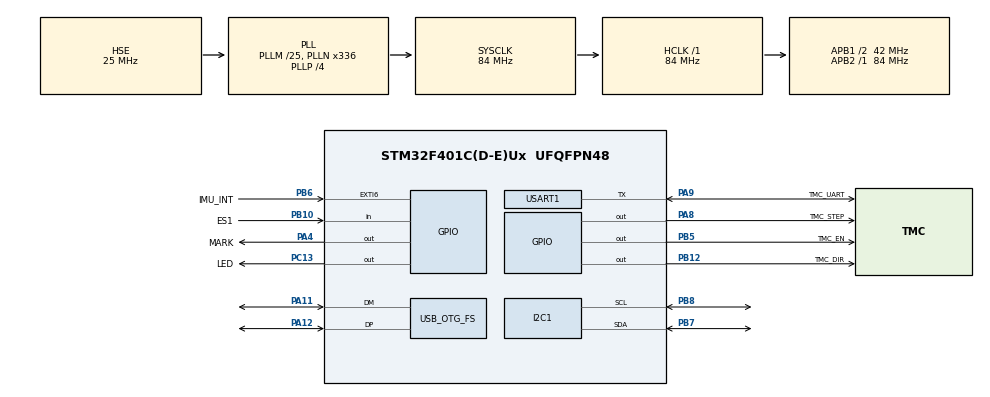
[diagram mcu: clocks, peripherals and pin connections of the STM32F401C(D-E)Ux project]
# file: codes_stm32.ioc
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Dma.I2C1_RX.0.Direction=DMA_PERIPH_TO_MEMORY
Dma.I2C1_RX.0.FIFOMode=DMA_FIFOMODE_DISABLE
Dma.I2C1_RX.0.Instance=DMA1_Stream0
Dma.I2C1_RX.0.MemDataAlignment=DMA_MDATAALIGN_BYTE
Dma.I2C1_RX.0.MemInc=DMA_MINC_ENABLE
Dma.I2C1_RX.0.Mode=DMA_NORMAL
Dma.I2C1_RX.0.PeriphDataAlignment=DMA_PDATAALIGN_BYTE
Dma.I2C1_RX.0.PeriphInc=DMA_PINC_DISABLE
Dma.I2C1_RX.0.Priority=DMA_PRIORITY_HIGH
Dma.Request0=I2C1_RX
I2C1.I2C_Mode=I2C_Fast
Mcu.Family=STM32F4
Mcu.Name=STM32F401C(D-E)Ux
Mcu.Package=UFQFPN48
NVIC.DMA1_Stream0_IRQn=true\:2\:0\:true\:false\:true\:false\:true\:true
NVIC.EXTI9_5_IRQn=true\:2\:0\:true\:false\:true\:true\:true\:true
NVIC.I2C1_ER_IRQn=true\:2\:0\:true\:false\:true\:true\:true\:true
NVIC.I2C1_EV_IRQn=true\:2\:0\:true\:false\:true\:true\:true\:true
NVIC.OTG_FS_IRQn=true\:4\:0\:true\:false\:true\:false\:true\:true
NVIC.PriorityGroup=NVIC_PRIORITYGROUP_4
PA11.Mode=Device_Only
PA11.Signal=USB_OTG_FS_DM
PA12.Mode=Device_Only
PA12.Signal=USB_OTG_FS_DP
PA13.Mode=Serial_Wire
PA13.Signal=SYS_JTMS-SWDIO
PA14.Mode=Serial_Wire
PA14.Signal=SYS_JTCK-SWCLK
PA4.GPIO_Label=MARK
PA4.Signal=GPIO_Output
PA8.GPIO_Label=TMC_STEP
PA8.Signal=GPIO_Output
PA9.GPIO_Label=TMC_UART
PA9.Mode=Half_duplex(single_wire_mode)
PA9.Signal=USART1_TX
PB10.GPIO_Label=ES1
PB10.GPIO_PuPd=GPIO_PULLUP
PB10.Signal=GPIO_Input
PB12.GPIO_Label=TMC_DIR
PB12.Signal=GPIO_Output
PB5.GPIO_Label=TMC_EN
PB5.PinState=GPIO_PIN_SET
PB5.Signal=GPIO_Output
PB6.GPIO_Label=IMU_INT
PB6.Signal=GPXTI6
PB7.GPIO_Pu=GPIO_PULLUP
PB7.Mode=I2C
PB7.Signal=I2C1_SDA
PB8.GPIO_Pu=GPIO_PULLUP
PB8.Mode=I2C
PB8.Signal=I2C1_SCL
PC13-ANTI_TAMP.GPIO_Label=LED
PC13-ANTI_TAMP.PinState=GPIO_PIN_SET
PC13-ANTI_TAMP.Signal=GPIO_Output
PH0\ -\ OSC_IN.Mode=HSE-External-Oscillator
PH0\ -\ OSC_IN.Signal=RCC_OSC_IN
PH1\ -\ OSC_OUT.Mode=HSE-External-Oscillator
PH1\ -\ OSC_OUT.Signal=RCC_OSC_OUT
ProjectManager.HeapSize=0x200
ProjectManager.StackSize=0x400
ProjectManager.TargetToolchain=STM32CubeIDE
RCC.48MHZClocksFreq_Value=48000000
RCC.AHBFreq_Value=84000000
RCC.APB1CLKDivider=RCC_HCLK_DIV2
RCC.APB1Freq_Value=42000000
RCC.APB1TimFreq_Value=84000000
RCC.APB2Freq_Value=84000000
RCC.APB2TimFreq_Value=84000000
RCC.CortexFreq_Value=84000000
RCC.HCLKFreq_Value=84000000
RCC.HSE_VALUE=25000000
RCC.HSI_VALUE=16000000
RCC.LSE_VALUE=32768
RCC.PLLM=25
RCC.PLLN=336
RCC.PLLP=RCC_PLLP_DIV4
RCC.PLLQ=7
RCC.SYSCLKFreq_VALUE=84000000
RCC.SYSCLKSource=RCC_SYSCLKSOURCE_PLLCLK
RCC.VCOOutputFreq_Value=336000000
USART1.VirtualMode=VM_ASYNC
USART1.VirtualMode-Half_duplex(single_wire_mode)=VM_ASYNC
USB_DEVICE.CLASS_NAME_FS=CDC
USB_DEVICE.VirtualMode-CDC_FS=Cdc
USB_DEVICE.VirtualModeFS=Cdc_FS
USB_OTG_FS.VirtualMode=Device_Only
VP_USB_DEVICE_VS_USB_DEVICE_CDC_FS.Mode=CDC_FS
board=custom

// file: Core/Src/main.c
/* USER CODE BEGIN Header */
/**
  ******************************************************************************
  * @file           : main.c
  * @brief          : Main program body
  ******************************************************************************
  * @attention
  *
  * Copyright (c) 2026 STMicroelectronics.
  * All rights reserved.
  *
  * This software is licensed under terms that can be found in the LICENSE file
  * in the root directory of this software component.
  * If no LICENSE file comes with this software, it is provided AS-IS.
  *
  ******************************************************************************
  */
/* USER CODE END Header */
#include "main.h"
#include "dma.h"
#include "i2c.h"
#include "usart.h"
#include "usb_device.h"
#include "gpio.h"

/* USER CODE BEGIN Includes */
#include "app.h"
/* USER CODE END Includes */

void SystemClock_Config(void);

int main(void)
{

  /* MCU Configuration--------------------------------------------------------*/

  /* Reset of all peripherals, Initializes the Flash interface and the Systick. */
  HAL_Init();

  /* Configure the system clock */
  SystemClock_Config();

  /* Initialize all configured peripherals */
  MX_GPIO_Init();
  MX_DMA_Init();
  MX_USB_DEVICE_Init();
  MX_I2C1_Init();
  MX_USART1_UART_Init();
  /* USER CODE BEGIN 2 */
  app_init();
  /* USER CODE END 2 */

  /* Infinite loop */
  while (1)
  {

    /* USER CODE BEGIN 3 */
    app_loop();
  }
  /* USER CODE END 3 */
}

void SystemClock_Config(void)
{
  RCC_OscInitTypeDef RCC_OscInitStruct = {0};
  RCC_ClkInitTypeDef RCC_ClkInitStruct = {0};

  /** Configure the main internal regulator output voltage
  */
  __HAL_RCC_PWR_CLK_ENABLE();
  __HAL_PWR_VOLTAGESCALING_CONFIG(PWR_REGULATOR_VOLTAGE_SCALE2);

  /** Initializes the RCC Oscillators according to the specified parameters
  * in the RCC_OscInitTypeDef structure.
  */
  RCC_OscInitStruct.OscillatorType = RCC_OSCILLATORTYPE_HSE;
  RCC_OscInitStruct.HSEState = RCC_HSE_ON;
  RCC_OscInitStruct.PLL.PLLState = RCC_PLL_ON;
  RCC_OscInitStruct.PLL.PLLSource = RCC_PLLSOURCE_HSE;
  RCC_OscInitStruct.PLL.PLLM = 25;
  RCC_OscInitStruct.PLL.PLLN = 336;
  RCC_OscInitStruct.PLL.PLLP = RCC_PLLP_DIV4;
  RCC_OscInitStruct.PLL.PLLQ = 7;
  if (HAL_RCC_OscConfig(&RCC_OscInitStruct) != HAL_OK)
  {
    Error_Handler();
  }

  /** Initializes the CPU, AHB and APB buses clocks
  */
  RCC_ClkInitStruct.ClockType = RCC_CLOCKTYPE_HCLK|RCC_CLOCKTYPE_SYSCLK
                              |RCC_CLOCKTYPE_PCLK1|RCC_CLOCKTYPE_PCLK2;
  RCC_ClkInitStruct.SYSCLKSource = RCC_SYSCLKSOURCE_PLLCLK;
  RCC_ClkInitStruct.AHBCLKDivider = RCC_SYSCLK_DIV1;
  RCC_ClkInitStruct.APB1CLKDivider = RCC_HCLK_DIV2;
  RCC_ClkInitStruct.APB2CLKDivider = RCC_HCLK_DIV1;

  if (HAL_RCC_ClockConfig(&RCC_ClkInitStruct, FLASH_LATENCY_2) != HAL_OK)
  {
    Error_Handler();
  }
}

void Error_Handler(void)
{
  /* USER CODE BEGIN Error_Handler_Debug */
  /* User can add his own implementation to report the HAL error return state */
  /* Disable the stepper driver (EN is active low) before stopping: the pull-up alone cannot
     override a pin still driven low. A register write, so it works from any context. */
  TMC_EN_GPIO_Port->BSRR = TMC_EN_Pin;
  __disable_irq();
  while (1)
  {
  }
  /* USER CODE END Error_Handler_Debug */
}
